# nrf9120_MLM1 register map
Vendor: Nordic Semiconductor; Series: nrf91; File version: 1
CPU: CM4 r0p1, little endian, MPU, FPU, 3 interrupt priority bits
Registers are 32-bit, read-write, reset 0x0 unless marked. A register's access mark holds for its fields unless they carry their own. Offsets are from the block's base; [hi:lo] are bit positions; lines under a group give offsets from that group; 'fields as' and 'values as' point back to an identical list.

## QDEC — Quadrature Decoder
Base 0x40013000
0x00 TASKS_START wo — Task starting the quadrature decoder
0x04 TASKS_STOP wo — Task stopping the quadrature decoder
0x08 TASKS_READCLRACC wo — Read and clear ACC and ACCDBL
0x0C TASKS_RDCLRACC wo — Read and clear ACC
0x10 TASKS_RDCLRDBL wo — Read and clear ACCDBL
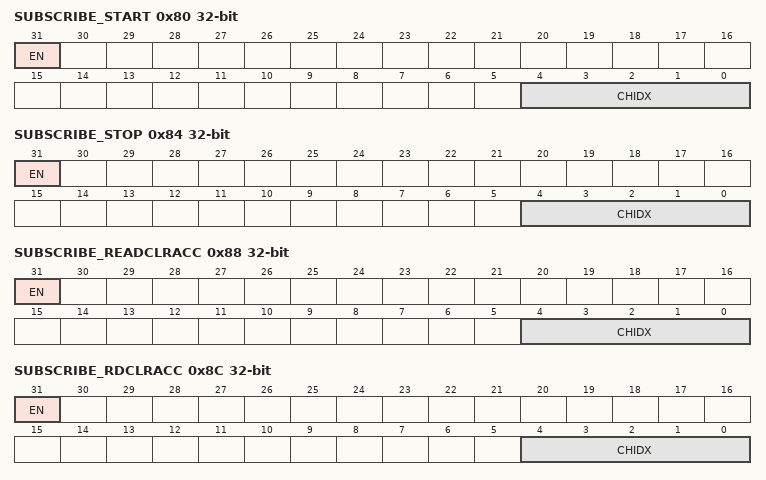
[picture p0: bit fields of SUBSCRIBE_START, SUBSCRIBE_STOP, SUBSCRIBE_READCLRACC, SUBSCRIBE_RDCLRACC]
0x80 SUBSCRIBE_START — Subscribe configuration for TASKS_START
  [31] EN
    0=Disabled (Disable subscription); 1=Enabled (Enable subscription)
  [4:0] CHIDX — Channel the TASKS_START will subscribe to.
0x84 SUBSCRIBE_STOP — Subscribe configuration for TASKS_STOP
  [31] EN
    values as SUBSCRIBE_START.EN
  [4:0] CHIDX — Channel the TASKS_STOP will subscribe to.
0x88 SUBSCRIBE_READCLRACC — Subscribe configuration for TASKS_READCLRACC
  [31] EN
    values as SUBSCRIBE_START.EN
  [4:0] CHIDX — Channel the TASKS_READCLRACC will subscribe to.
0x8C SUBSCRIBE_RDCLRACC — Subscribe configuration for TASKS_RDCLRACC
  [31] EN
    values as SUBSCRIBE_START.EN
  [4:0] CHIDX — Channel the TASKS_RDCLRACC will subscribe to.
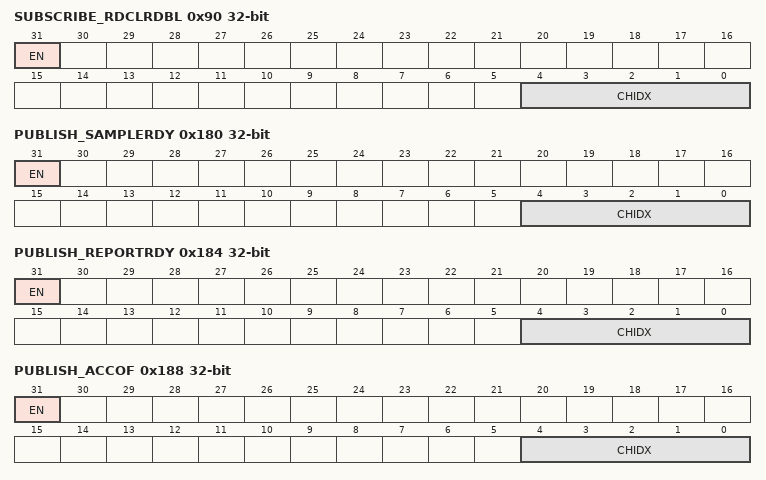
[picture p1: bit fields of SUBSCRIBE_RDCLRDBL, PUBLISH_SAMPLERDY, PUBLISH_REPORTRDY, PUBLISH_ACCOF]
0x90 SUBSCRIBE_RDCLRDBL — Subscribe configuration for TASKS_RDCLRDBL
  [31] EN
    values as SUBSCRIBE_START.EN
  [4:0] CHIDX — Channel the TASKS_RDCLRDBL will subscribe to.
0x100 EVENTS_SAMPLERDY — Event being generated for every new sample value written to the SAMPLE register
0x104 EVENTS_REPORTRDY — Non-null report ready
0x108 EVENTS_ACCOF — ACC or ACCDBL register overflow
0x10C EVENTS_DBLRDY — Double displacement(s) detected
0x110 EVENTS_STOPPED — QDEC has been stopped
0x180 PUBLISH_SAMPLERDY — Publish configuration for EVENTS_SAMPLERDY
  [31] EN
    0=Disabled (Disable publishing); 1=Enabled (Enable publishing)
  [4:0] CHIDX — Channel the EVENTS_SAMPLERDY will subscribe to.
0x184 PUBLISH_REPORTRDY — Publish configuration for EVENTS_REPORTRDY
  [31] EN
    values as PUBLISH_SAMPLERDY.EN
  [4:0] CHIDX — Channel the EVENTS_REPORTRDY will subscribe to.
0x188 PUBLISH_ACCOF — Publish configuration for EVENTS_ACCOF
  [31] EN
    values as PUBLISH_SAMPLERDY.EN
  [4:0] CHIDX — Channel the EVENTS_ACCOF will subscribe to.
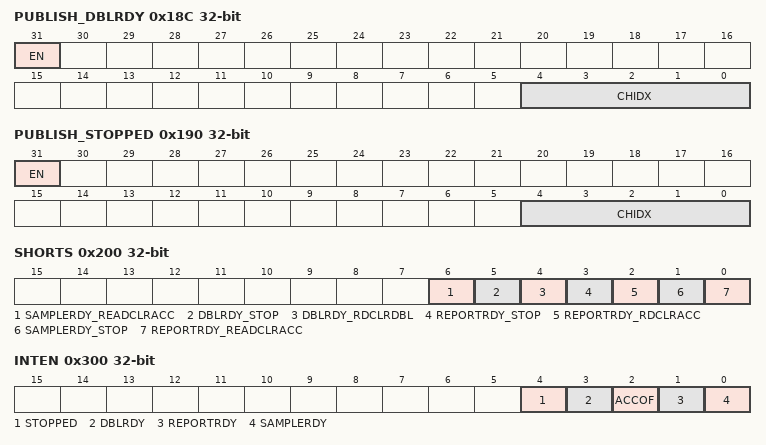
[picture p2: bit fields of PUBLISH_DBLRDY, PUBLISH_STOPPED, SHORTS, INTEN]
0x18C PUBLISH_DBLRDY — Publish configuration for EVENTS_DBLRDY
  [31] EN
    values as PUBLISH_SAMPLERDY.EN
  [4:0] CHIDX — Channel the EVENTS_DBLRDY will subscribe to.
0x190 PUBLISH_STOPPED — Publish configuration for EVENTS_STOPPED
  [31] EN
    values as PUBLISH_SAMPLERDY.EN
  [4:0] CHIDX — Channel the EVENTS_STOPPED will subscribe to.
0x200 SHORTS — Shortcut register
  [all] fields
    0=Disabled (Disable shortcut); 1=Enabled (Enable shortcut)
  [6] SAMPLERDY_READCLRACC — Shortcut between SAMPLERDY event and READCLRACC task
  [5] DBLRDY_STOP — Shortcut between DBLRDY event and STOP task
  [4] DBLRDY_RDCLRDBL — Shortcut between DBLRDY event and RDCLRDBL task
  [3] REPORTRDY_STOP — Shortcut between REPORTRDY event and STOP task
  [2] REPORTRDY_RDCLRACC — Shortcut between REPORTRDY event and RDCLRACC task
  [1] SAMPLERDY_STOP — Shortcut between SAMPLERDY event and STOP task
  [0] REPORTRDY_READCLRACC — Shortcut between REPORTRDY event and READCLRACC task
0x300 INTEN — Enable or disable interrupt
  [all] fields
    0=Disabled; 1=Enabled
  [4] STOPPED — Enable or disable interrupt for STOPPED event
  [3] DBLRDY — Enable or disable interrupt for DBLRDY event
  [2] ACCOF — Enable or disable interrupt for ACCOF event
  [1] REPORTRDY — Enable or disable interrupt for REPORTRDY event
  [0] SAMPLERDY — Enable or disable interrupt for SAMPLERDY event
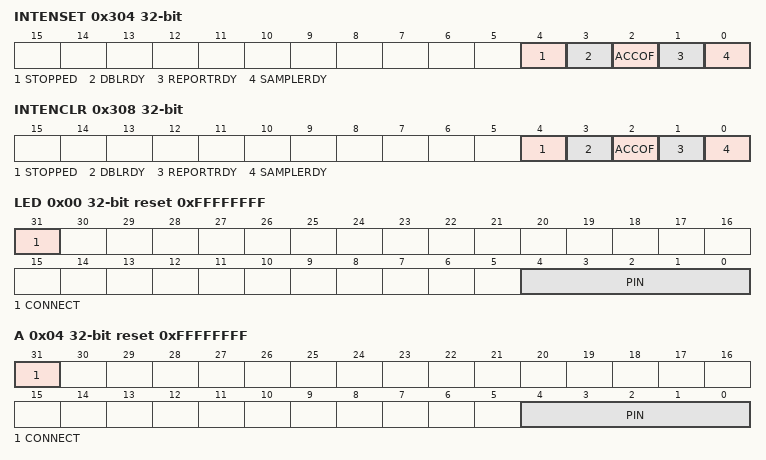
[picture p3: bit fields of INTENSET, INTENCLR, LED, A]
0x304 INTENSET — Enable interrupt
  [all] fields
    on read: 0=Disabled (Read: Disabled); 1=Enabled (Read: Enabled) | on write: 1=Set (Enable)
  [4] STOPPED — Write '1' to Enable interrupt for STOPPED event
  [3] DBLRDY — Write '1' to Enable interrupt for DBLRDY event
  [2] ACCOF — Write '1' to Enable interrupt for ACCOF event
  [1] REPORTRDY — Write '1' to Enable interrupt for REPORTRDY event
  [0] SAMPLERDY — Write '1' to Enable interrupt for SAMPLERDY event
0x308 INTENCLR — Disable interrupt
  [all] fields
    on read: 0=Disabled (Read: Disabled); 1=Enabled (Read: Enabled) | on write: 1=Clear (Disable)
  [4] STOPPED — Write '1' to Disable interrupt for STOPPED event
  [3] DBLRDY — Write '1' to Disable interrupt for DBLRDY event
  [2] ACCOF — Write '1' to Disable interrupt for ACCOF event
  [1] REPORTRDY — Write '1' to Disable interrupt for REPORTRDY event
  [0] SAMPLERDY — Write '1' to Disable interrupt for SAMPLERDY event
0x500 ENABLE — Enable the quadrature decoder
  [0] ENABLE — Enable or disable the quadrature decoder
    0=Disabled; 1=Enabled
0x504 LEDPOL — LED output pin polarity
  [0] LEDPOL
    0=ActiveLow (Led active on output pin low); 1=ActiveHigh (Led active on output pin high)
0x508 SAMPLEPER — Sample period
  [3:0] SAMPLEPER — Sample period. The SAMPLE register will be updated for every new sample
    0=128us; 1=256us; 2=512us; 3=1024us; 4=2048us; 5=4096us; 6=8192us; 7=16384us; 8=32ms (32768 us); 9=65ms (65536 us); 10=131ms (131072 us)
0x50C SAMPLE ro — Motion sample value
  [31:0] SAMPLE — Last motion sample
0x510 REPORTPER — Number of samples to be taken before REPORTRDY and DBLRDY events can be generated
  [3:0] REPORTPER — Specifies the number of samples to be accumulated in the ACC register before the REPORTRDY and DBLRDY events can be generated
    0=10Smpl (10 samples / report); 1=40Smpl (40 samples / report); 2=80Smpl (80 samples / report); 3=120Smpl (120 samples / report); 4=160Smpl (160 samples / report); 5=200Smpl (200 samples / report); 6=240Smpl (240 samples / report); 7=280Smpl (280 samples / report); 8=1Smpl (1 sample / report)
0x514 ACC ro — Register accumulating the valid transitions
  [31:0] ACC — Register accumulating all valid samples (not double transition) read from the SAMPLE register
0x518 ACCREAD ro — Snapshot of the ACC register, updated by the READCLRACC or RDCLRACC task
  [31:0] ACCREAD — Snapshot of the ACC register.
0x51C PSEL group — Unspecified
  0x00 LED reset 0xFFFFFFFF — Pin select for LED signal
    [31] CONNECT — Connection
      1=Disconnected; 0=Connected
    [4:0] PIN — Pin number
  0x04 A reset 0xFFFFFFFF — Pin select for A signal
    fields as PSEL.LED
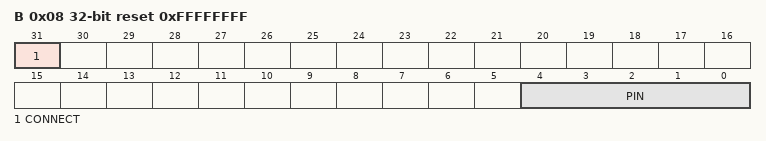
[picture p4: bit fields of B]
  0x08 B reset 0xFFFFFFFF — Pin select for B signal
    fields as PSEL.LED
0x528 DBFEN — Enable input debounce filters
  [0] DBFEN
    0=Disabled (Debounce input filters disabled); 1=Enabled (Debounce input filters enabled)
0x540 LEDPRE reset 0x10 — Time period the LED is switched ON prior to sampling
  [8:0] LEDPRE — Period in us the LED is switched on prior to sampling
0x544 ACCDBL ro — Register accumulating the number of detected double transitions
  [3:0] ACCDBL — Register accumulating the number of detected double or illegal transitions. ( SAMPLE = 2 ).
0x548 ACCDBLREAD ro — Snapshot of the ACCDBL, updated by the READCLRACC or RDCLRDBL task
  [3:0] ACCDBLREAD — Snapshot of the ACCDBL register. This field is updated when the READCLRACC or RDCLRDBL task is triggered.
0xFFC POWER reset 0x1 — Peripheral power control
  [0] POWER — Peripheral power control. The peripheral and its registers will be reset to its initial state by switching the peripheral off and then back on again.
    0=Disabled (Peripheral is powered off); 1=Enabled (Peripheral is powered on)
